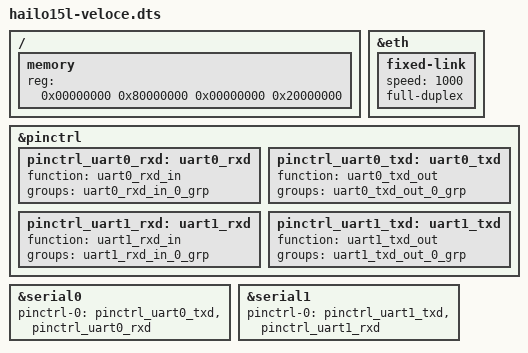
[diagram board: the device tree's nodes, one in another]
// SPDX-License-Identifier:     GPL-2.0
/*
 * Copyright (c) 2019-2024 Hailo Technologies Ltd. All rights reserved.
 */

/dts-v1/;

#include "hailo15l-base.dtsi"

/ {
    memory {
        device_type = "memory";
        reg = <0x00000000 0x80000000 0x00000000 0x20000000>;
    };
};

&eth {
    status = "okay";
    fixed-link {
        speed = <1000>;
        full-duplex;
    };
};

&pinctrl {
    pinctrl_uart0_rxd: uart0_rxd {
        function = "uart0_rxd_in";
        groups = "uart0_rxd_in_0_grp";
    };

    pinctrl_uart0_txd: uart0_txd {
        function = "uart0_txd_out";
        groups = "uart0_txd_out_0_grp";
    };

    pinctrl_uart1_rxd: uart1_rxd {
        function = "uart1_rxd_in";
        groups = "uart1_rxd_in_0_grp";
    };

    pinctrl_uart1_txd: uart1_txd {
        function = "uart1_txd_out";
        groups = "uart1_txd_out_0_grp";
    };
};

&serial0 {
    status = "okay";
    pinctrl-names = "default";
    pinctrl-0 = <&pinctrl_uart0_txd>, <&pinctrl_uart0_rxd>;
};

&serial1 {
    status = "okay";
    pinctrl-names = "default";
    pinctrl-0 = <&pinctrl_uart1_txd>, <&pinctrl_uart1_rxd>;
};
